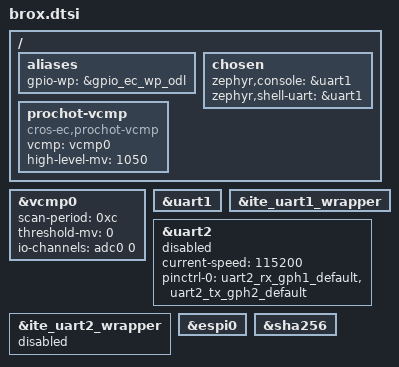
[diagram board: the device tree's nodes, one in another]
/* Copyright 2023 The ChromiumOS Authors
 * Use of this source code is governed by a BSD-style license that can be
 * found in the LICENSE file.
 */

/ {
	aliases {
		gpio-wp = &gpio_ec_wp_odl;
	};
	chosen {
		zephyr,console = &uart1;
		zephyr,shell-uart = &uart1;
	};

	prochot-vcmp {
		compatible = "cros-ec,prochot-vcmp";
		vcmp = <&vcmp0>;
		high-level-mv = <1050>;
	};
};

&vcmp0 {
	status = "okay";
	scan-period = <0xc>;
	threshold-mv = <0>;
	io-channels = <&adc0 0>;
};

/* UART interface is SIN1/SOUT1 pins, which ITE maps to devicetree uart2 */
&uart1 {
	status = "okay";
};

&ite_uart1_wrapper {
	status = "okay";
};

&uart2 {
	status = "disabled";
	current-speed = <115200>;
	pinctrl-0 = <&uart2_rx_gph1_default
		     &uart2_tx_gph2_default>;
	pinctrl-names = "default";
};

&ite_uart2_wrapper {
	status = "disabled";
};

&espi0 {
	status = "okay";
};

&sha256 {
	status = "okay";
};
